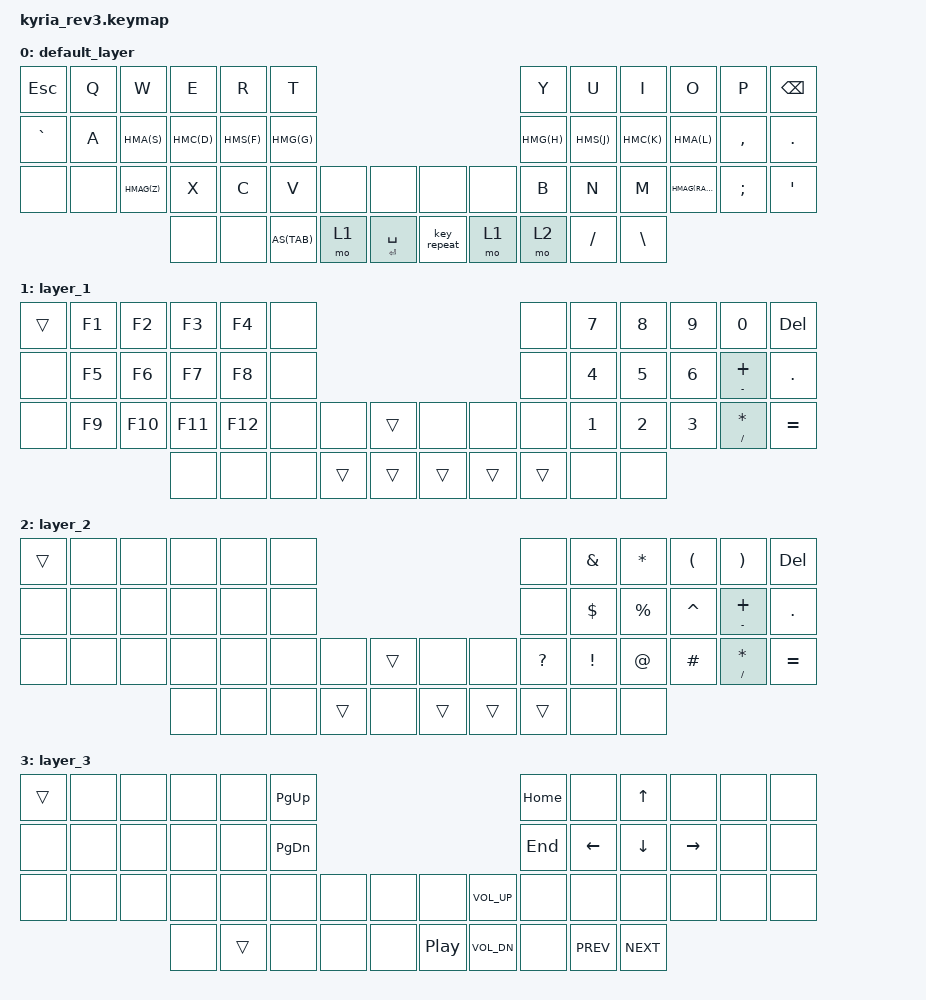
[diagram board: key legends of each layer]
// Copyright (c) 2023 The ZMK Contributors
// SPDX-License-Identifier: MIT

#include <behaviors.dtsi>
#include <dt-bindings/zmk/keys.h>
#include <dt-bindings/zmk/rgb.h>

&led_strip { chain-length = <31>; };

//    autoshift mod
    #define AS(keycode) &as LS(keycode) keycode
//    homerow mods
    #define HMA(keycode) &hm LALT keycode
    #define HMC(keycode) &hm LCTRL keycode
    #define HMG(keycode) &hm LGUI keycode
    #define HMS(keycode) &hm LSHIFT keycode
    #define HMAG(keycode) &hm RALT keycode
//    other mods
    #define SPC &mt ENTER SPACE
    #define REDO &key_repeat
    #define PM &mt MINUS PLUS
    #define MD &mt FSLH STAR
    #define PLAY &kp C_PLAY_PAUSE
    #define PREV &kp C_PREV
    #define NEXT &kp C_NEXT

//    layer names
    #define BASE 0
    #define LOWER 1
    #define RAISE 2
    #define COMBO 3

/ {
    behaviors {
        hm: homerow_mods {
            compatible = "zmk,behavior-hold-tap";
            label = "HOMEROW_MOD";
            #binding-cells = <2>;
            tapping_term_ms = <200>;
            quick_tap_ms = <0>;
            flavor = "tap-preferred";
            bindings = <&kp>, <&kp>;
        };
        as: auto_shift {
            compatible = "zmk,behavior-hold-tap";
            label = "AUTO_SHIFT";
            #binding-cells = <2>;
            tapping_term_ms = <150>;
            quick_tap_ms = <0>;
            flavor = "tap-preferred";
            bindings = <&kp>, <&kp>;
        };
    };
    conditional_layers {
        compatible = "zmk,conditional-layers";
        tri_layer {
            if-layers = <LOWER RAISE>;
            then-layer = <COMBO>;
        };
    };
            // ---------------------------------------------------------------------------------------------------------------------
            // ~ ____ | ____ | ____ | ____ | ____ | ____ ~              ~~~              ~ ____ | ____ | ____ | ____ | ____ | ____ ~
// homerow  // ~ ____ | ____ | LALT | CTRL |SHIFT | GUI  ~              ~~~              ~ GUI  |SHIFT | CTRL | LALT | ____ | ____ ~
            // ~ ____ | ____ | ALTG | ____ | ____ | ____ ~              ~~~              ~ ____ | ____ | ____ | ____ | ____ | ____ ~
            //                   ~ ____ |      | ____ ~~~~ ____ |      ~~~~~      | ____ ~~~~ ____ | ____ | ____ ~
            // ---------------------------------------------------------------------------------------------------------------------
            // | ESC  |  Q   |  W   |  E   |  R   |  T   |              ~~~              |  Y   |  U   |  I   |  O   |  P   | BSPC |
// default  // |  `   |- A  -|- S  -|- D  -|- F  -|- G  -|              ~~~              |- H  -|- J  -|- K  -|- L  -|  ,   |  .   |
            // | ____ | ____ |- Z  -|  X   |  C   |  V   | ____ | ____ |~~~| ____ | ____ |  B   |  N   |- M  -| ____ |  ;   |  '   |
            //                   | ____ | ____ | TAB+ |~~|LOWER | SPC+ |~~~| REDO |LOWER |~~|RAISE |  /   |  \   |
            // ---------------------------------------------------------------------------------------------------------------------
            // ~[    ]|[ F1 ]|[ F2 ]|[ F3 ]|[ F4 ]|[____]~              ~~~              ~[____]|[ 7  ]|[ 8  ]|[ 9  ]|[ 0  ]|[DEL ]~
// lower    // ~[____]|[ F5 ]|[ F6 ]|[ F7 ]|[ F8 ]|[____]~              ~~~              ~[____]|[ 4  ]|[ 5  ]|[ 6  ]|[ +- ]|[ .  ]~
            // ~[____]|[ F9 ]|[F10 ]|[F11 ]|[F12 ]|[____]|[____]|[    ]~~~~~[____]|[____]|[____]|[ 1  ]|[ 2  ]|[ 3  ]|[ */ ]|[ =  ]~
            //                   ~[____]|[____]|[    ]~~~~[    ]|[    ]~~~~~[    ]|[    ]~~~~[____]|[____]|[____]~
            // ---------------------------------------------------------------------------------------------------------------------
            // ~[    ]|[____]|[____]|[____]|[____]|[____]~              ~~~              ~[____]|[ &  ]|[ *  ]|[ (  ]|[ )  ]|[DEL ]~
// raise    // ~[____]|[____]|[____]|[____]|[____]|[____]~              ~~~              ~[____]|[ $  ]|[ %  ]|[ ^  ]|[____]|[____]~
            // ~[____]|[____]|[____]|[____]|[____]|[____]|[____]|[    ]~~~~~[____]|[____]|[ ?  ]|[ !  ]|[ @  ]|[ #  ]|[____]|[____]~
            //                   ~[____]|[    ]|[____]~~~~[____]|[    ]~~~~~[    ]|[____]~~~~[____]|[____]|[____]~
            // ---------------------------------------------------------------------------------------------------------------------
            // ~[    ]~[____]~[____]~[____]~[____]~[PGUP]~              ~~~              ~[HOME]~[____]~[ ↑  ]~[____]~[____]~[____]~
combo       // ~[____]~[____]~[____]~[____]~[____]~[PGDN]~              ~~~              ~[END ]~[ ←  ]~[ ↓  ]~[ →  ]~[____]~[____]~
            // ~[____]~[____]~[____]~[____]~[____]~[____]~[____]~[____]~~~~~[____]~[VOL+]~[____]~[____]~[____]~[____]~[____]~[____]~
            //                   ~[____]~[    ]~[____]~~~~[____]~[____]~~~~~[ >| ]~[VOL-]~~~~[____]~[ << ]~[ >> ]~
            // ---------------------------------------------------------------------------------------------------------------------
    keymap {
        compatible = "zmk,keymap";
        default_layer { bindings = <
 &kp  ESC  &kp Q    &kp W   &kp E    &kp R    &kp T                             &kp Y      &kp U     &kp I       &kp O      &kp P  &kp BSPC
&kp GRAVE  &kp A   HMA(S)  HMC(D)   HMS(F)   HMG(G)                             HMG(H)     HMS(J)    HMC(K)     HMA(L)  &kp COMMA   &kp DOT
    &none  &none  HMAG(Z)   &kp X    &kp C    &kp V  &none  &none  &none  &none  &kp B     &kp N     &kp M  HMAG(RALT)   &kp SEMI   &kp SQT
                            &none    &none  AS(TAB)  &mo 1    SPC   REDO  &mo 1  &mo 2  &kp FSLH  &kp BSLH
            >;      sensor-bindings = <&inc_dec_kp C_VOL_UP C_VOL_DN &inc_dec_kp PG_UP PG_DN>;
        };          layer_1 { bindings = <
&trans  &kp F1   &kp F2   &kp F3   &kp F4  &none                                   &none  &kp N7  &kp N8  &kp N9  &kp N0    &kp DEL
 &none  &kp F5   &kp F6   &kp F7   &kp F8  &none                                   &none  &kp N4  &kp N5  &kp N6      PM    &kp DOT
 &none  &kp F9  &kp F10  &kp F11  &kp F12  &none   &none  &trans   &none   &none   &none  &kp N1  &kp N2  &kp N3      MD  &kp EQUAL
                           &none   &none   &none  &trans  &trans  &trans  &trans  &trans   &none   &none
        >; };       layer_2 { bindings = <
&trans  &none  &none  &none  &none   &none                                    &none  &kp AMPS   &kp STAR   &kp LPAR  &kp RPAR    &kp DEL
 &none  &none  &none  &none  &none   &none                                    &none  &kp DLLR  &kp PRCNT  &kp CARET        PM    &kp DOT
 &none  &none  &none  &none  &none   &none  &none  &trans   &none  &none  &kp QMARK  &kp EXCL     &kp AT   &kp HASH        MD  &kp EQUAL
                             &none   &none   &none &trans   &none  &trans  &trans &trans   &none   &none
        >; };       layer_3 { bindings = <
&trans  &none  &none  &none   &none  &kp PG_UP                                  &kp HOME     &none    &kp UP      &none  &none  &none
 &none  &none  &none  &none   &none  &kp PG_DN                                   &kp END  &kp LEFT  &kp DOWN  &kp RIGHT  &none  &none
 &none  &none  &none  &none   &none      &none  &none  &none  &none  &kp C_VOL_UP  &none     &none     &none      &none  &none  &none
                      &none  &trans      &none  &none  &none   PLAY  &kp C_VOL_DN  &none      PREV      NEXT
>; }; };
};
